# BAT32A237 register map
Vendor: CMS; Series: BAT32A237; File version: 1.2
CPU: CM0+ r0p1, little endian, MPU, no FPU, VTOR, 2 interrupt priority bits
Registers are 8-bit, read-write, reset 0x0 unless marked. A register's access mark holds for its fields unless they carry their own. Offsets are from the block's base; [hi:lo] are bit positions; 'fields as' and 'values as' point back to an identical list.

## TMM — BLDC Motor control Timer M
Base 0x40042A60
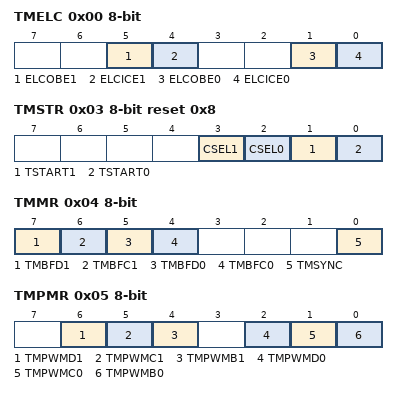
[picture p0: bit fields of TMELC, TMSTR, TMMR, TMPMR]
0x00 TMELC — Timer ELC register
  [5] ELCOBE1 — ELC event input 1 enable for timer M pulse output forced cutoff
  [4] ELCICE1 — ELC event input 1 select for timer M input capture D1
  [1] ELCOBE0 — ELC event input 0 enable for timer M pulse output forced cutoff
  [0] ELCICE0 — ELC event input 0 select for timer M input capture D0
0x03 TMSTR reset 0x8 — Timer start register
  [3] CSEL1 — TM1 count operation select
  [2] CSEL0 — TM0 count operation select
  [1] TSTART1 — TM1 count start flag
  [0] TSTART0 — TM0 count start flag
0x04 TMMR — Timer mode register
  [7] TMBFD1 — TMGRD1 register function select
  [6] TMBFC1 — TMGRC1 register function select
  [5] TMBFD0 — TMGRD0 register function select
  [4] TMBFC0 — TMGRC0 register function select
  [0] TMSYNC — TMs synchronous
0x05 TMPMR — PWM function select register
  [6] TMPWMD1 — PWM function of TMIOD1 select
  [5] TMPWMC1 — PWM function of TMIOC1 select
  [4] TMPWMB1 — PWM function of TMIOB1 select
  [2] TMPWMD0 — PWM function of TMIOD0 select
  [1] TMPWMC0 — PWM function of TMIOC0 select
  [0] TMPWMB0 — PWM function of TMIOB0 select
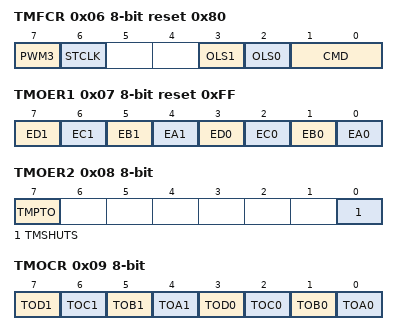
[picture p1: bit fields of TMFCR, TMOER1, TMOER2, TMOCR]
0x06 TMFCR reset 0x80 — Timer function control register
  [7] PWM3 — PWM3 mode select
  [6] STCLK — External clock input select
  [3] OLS1 — Counter-Phase output level select
  [2] OLS0 — Phase output level select
  [1:0] CMD — Combination mode select
0x07 TMOER1 reset 0xFF — Timer output master enable register 1
  [7] ED1 — TMIOD1 output disable
  [6] EC1 — TMIOC1 output disable
  [5] EB1 — TMIOB1 output disable
  [4] EA1 — TMIOA1 output disable
  [3] ED0 — TMIOD0 output disable
  [2] EC0 — TMIOC0 output disable
  [1] EB0 — TMIOB0 output disable
  [0] EA0 — TMIOA0 output disable
0x08 TMOER2 — Timer output master enable register 2
  [7] TMPTO — INTP0 pin of pulse output forced cutoff signal input enabled
  [0] TMSHUTS — Forced cutoff flag
0x09 TMOCR — Timer output control register
  [7] TOD1 — TMIOD1 initial output level select
  [6] TOC1 — TMIOC1 initial output level select
  [5] TOB1 — TMIOB1 initial output level select
  [4] TOA1 — TMIOA1 initial output level select
  [3] TOD0 — TMIOD0 initial output level select
  [2] TOC0 — TMIOC0 initial output level select
  [1] TOB0 — TMIOB0 initial output level select
  [0] TOA0 — TMIOA0 initial output level select
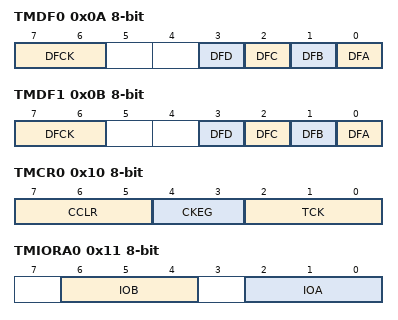
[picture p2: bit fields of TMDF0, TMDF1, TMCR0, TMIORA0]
0x0A TMDF0 — Digital filter function select register 0
  [7:6] DFCK — Clock select for digital filter function
  [3] DFD — TMIODi pin digital filter function select
  [2] DFC — TMIOCi pin digital filter function select
  [1] DFB — TMIOBi pin digital filter function select
  [0] DFA — TMIOAi pin digital filter function select
0x0B TMDF1 — Digital filter function select register 1
  fields as TMDF0
0x10 TMCR0 — Timer control register 0
  [7:5] CCLR — TMi counter clear select
  [4:3] CKEG — External clock edge select
  [2:0] TCK — Count source select
0x11 TMIORA0 — Timer I/O control register A0
  [6:4] IOB — TMGRB mode control
  [2:0] IOA — TMGRA mode control
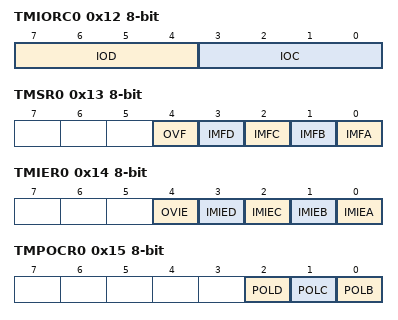
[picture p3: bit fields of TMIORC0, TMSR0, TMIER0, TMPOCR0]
0x12 TMIORC0 — Timer I/O control register C0
  [7:4] IOD — TMGRD mode control
  [3:0] IOC — TMGRC mode control
0x13 TMSR0 — Timer status register 0
  [4] OVF — Overflow flag
  [3] IMFD — Input capture/compare match flag D
  [2] IMFC — Input capture/compare match flag C
  [1] IMFB — Input capture/compare match flag B
  [0] IMFA — Input capture/compare match flag A
0x14 TMIER0 — Timer interrupt enable register 0
  [4] OVIE — Overflow/underflow interrupt enable
  [3] IMIED — Input capture/compare match interrupt enable D
  [2] IMIEC — Input capture/compare match interrupt enable C
  [1] IMIEB — Input capture/compare match interrupt enable B
  [0] IMIEA — Input capture/compare match interrupt enable A
0x15 TMPOCR0 — PWM output level control register 0
  [2] POLD — PWM output level control D
  [1] POLC — PWM output level control C
  [0] POLB — PWM output level control B
0x16 TM0 16-bit — Timer M counter 0
0x18 TMGRA0 16-bit reset 0xFFFF — Timer M general register A0
0x1A TMGRB0 16-bit reset 0xFFFF — Timer M general register B0
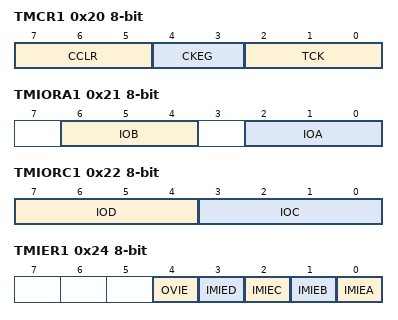
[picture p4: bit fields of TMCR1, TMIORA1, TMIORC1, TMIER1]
0x20 TMCR1 — Timer control register 1
  fields as TMCR0
0x21 TMIORA1 — Timer I/O control register A1
  [6:4] IOB — TMGRB mode control
  [2:0] IOA — TMGRA mode control
0x22 TMIORC1 — Timer I/O control register C1
  [7:4] IOD — TMGRD mode control
  [3:0] IOC — TMGRC mode control
0x23 TMSR1 — Timer status register 1
  [5] UDF — Underflow flag
0x24 TMIER1 — Timer interrupt enable register 1
  fields as TMIER0
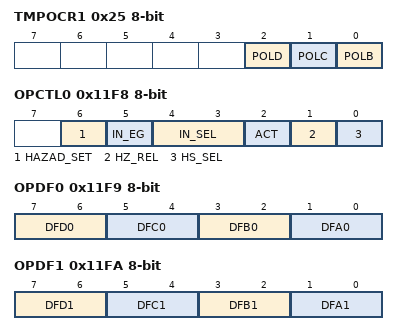
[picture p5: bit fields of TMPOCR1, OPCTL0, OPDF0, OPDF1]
0x25 TMPOCR1 — PWM output level control register 1
  fields as TMPOCR0
0x26 TM1 16-bit — Timer M counter 1
0x28 TMGRA1 16-bit reset 0xFFFF — Timer M general register A1
0x2A TMGRB1 16-bit reset 0xFFFF — Timer M general register B1
0xF8 TMGRC0 16-bit reset 0xFFFF — Timer M general register C0
0xFA TMGRD0 16-bit reset 0xFFFF — Timer M general register D0
0xFC TMGRC1 16-bit reset 0xFFFF — Timer M general register C1
0xFE TMGRD1 16-bit reset 0xFFFF — Timer M general register D1
0x11F8 OPCTL0 — PWMOPA control register 0
  [6] HAZAD_SET — Output cutoff hazard control selection
  [5] IN_EG — Output forced cutoff source edge/output forced cutoff release edge selection
  [4:3] IN_SEL — Cutoff source selection
  [2] ACT — When software release is selected: Software release timing selection
  [1] HZ_REL — When software release is selected: Output cutoff release control
  [0] HS_SEL — Output forced cutoff release mode selection
0x11F9 OPDF0 — PWMOPA cutoff control register 0
  [7:6] DFD0 — TMIOD0 pin output forced cutoff control
  [5:4] DFC0 — TMIOC0 pin output forced cutoff control
  [3:2] DFB0 — TMIOB0 pin output forced cutoff control
  [1:0] DFA0 — TMIOA0 pin output forced cutoff control
0x11FA OPDF1 — PWMOPA cutoff control register 1
  [7:6] DFD1 — TMIOD1 pin output forced cutoff control
  [5:4] DFC1 — TMIOC1 pin output forced cutoff control
  [3:2] DFB1 — TMIOB1 pin output forced cutoff control
  [1:0] DFA1 — TMIOA1 pin output forced cutoff control
0x11FB OPEDGE — PWMOPA edge selection register
  [1:0] EG — Output forced cutoff release edge selection
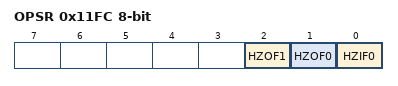
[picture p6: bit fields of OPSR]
0x11FC OPSR ro — PWMOPA status register
  [2] HZOF1 — cutoff state
  [1] HZOF0 — cutoff state
  [0] HZIF0 — Output cutoff source state
